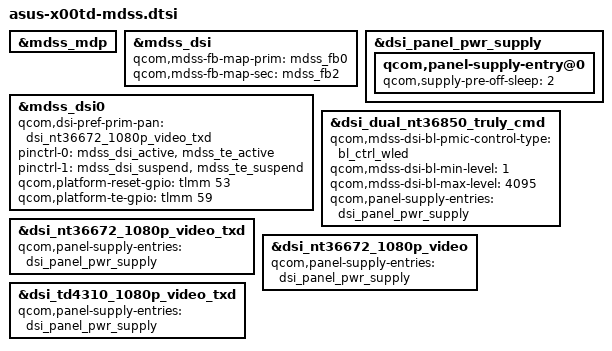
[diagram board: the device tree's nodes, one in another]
// SPDX-License-Identifier: GPL-2.0
// Copyright (C) 2021 Atom-X-Devs < https://www.github.com/Atom-X-Devs >

// asus X00TD mdss changes
&mdss_mdp {
	#include "display/dsi-panel-nt36672-1080p-video.dtsi"
	#include "display/dsi-panel-td4310-1080p-video-txd.dtsi"
	#include "display/dsi-panel-nt36672-1080p-video-txd.dtsi"
};

&mdss_dsi {
	qcom,mdss-fb-map-prim = <&mdss_fb0>;
	qcom,mdss-fb-map-sec = <&mdss_fb2>;
};

&dsi_panel_pwr_supply {
	qcom,panel-supply-entry@0 {
		qcom,supply-pre-off-sleep = <2>;
	};
};

&mdss_dsi0 {
	qcom,dsi-pref-prim-pan = <&dsi_nt36672_1080p_video_txd>;
	pinctrl-names = "mdss_default", "mdss_sleep";
	pinctrl-0 = <&mdss_dsi_active &mdss_te_active>;
	pinctrl-1 = <&mdss_dsi_suspend &mdss_te_suspend>;
	qcom,platform-reset-gpio = <&tlmm 53 0>;
	qcom,platform-te-gpio = <&tlmm 59 0>;
};

&dsi_dual_nt36850_truly_cmd {
	qcom,mdss-dsi-bl-pmic-control-type = "bl_ctrl_wled";
	qcom,mdss-dsi-bl-min-level = <1>;
	qcom,mdss-dsi-bl-max-level = <4095>;
	qcom,panel-supply-entries = <&dsi_panel_pwr_supply>;
};

&dsi_nt36672_1080p_video_txd {
	qcom,panel-supply-entries = <&dsi_panel_pwr_supply>;
};

&dsi_nt36672_1080p_video {
	qcom,panel-supply-entries = <&dsi_panel_pwr_supply>;
};

&dsi_td4310_1080p_video_txd {
	qcom,panel-supply-entries = <&dsi_panel_pwr_supply>;
};
